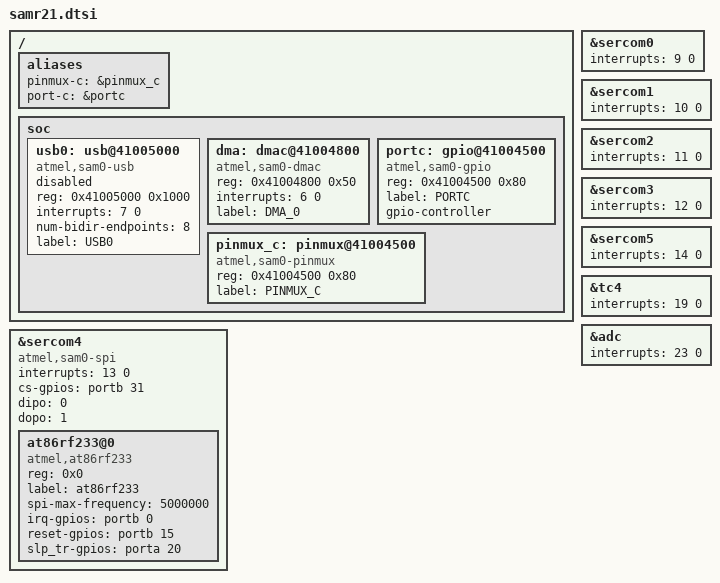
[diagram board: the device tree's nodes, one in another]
/*
 * Copyright (c) 2019 Benjamin Valentin
 *
 * SPDX-License-Identifier: Apache-2.0
 */

#include <atmel/samd.dtsi>

/ {
	aliases {
		pinmux-c = &pinmux_c;
		port-c = &portc;
	};

	soc {
		usb0: usb@41005000 {
			compatible = "atmel,sam0-usb";
			status = "disabled";
			reg = <0x41005000 0x1000>;
			interrupts = <7 0>;
			num-bidir-endpoints = <8>;
			label = "USB0";
		};

		dma: dmac@41004800 {
			compatible = "atmel,sam0-dmac";
			reg = <0x41004800 0x50>;
			interrupts = <6 0>;
			label = "DMA_0";
		};

		portc: gpio@41004500 {
			compatible = "atmel,sam0-gpio";
			reg = <0x41004500 0x80>;
			label = "PORTC";
			gpio-controller;
			#gpio-cells = <2>;
		};

		pinmux_c: pinmux@41004500 {
			compatible = "atmel,sam0-pinmux";
			reg = <0x41004500 0x80>;
			label = "PINMUX_C";
		};
	};
};

&sercom0 {
	interrupts = <9 0>;
};

&sercom1 {
	interrupts = <10 0>;
};

&sercom2 {
	interrupts = <11 0>;
};

&sercom3 {
	interrupts = <12 0>;
};

&sercom4 {
	interrupts = <13 0>;

	status = "ok";

	compatible = "atmel,sam0-spi";
	cs-gpios = <&portb 31 0>;
	dipo = <0>;
	dopo = <1>;

	#address-cells = <1>;
	#size-cells = <0>;

	at86rf233@0 {
		reg = <0x0>;
		compatible = "atmel,at86rf233";
		label = "at86rf233";
		spi-max-frequency = <5000000>;
		irq-gpios = <&portb 0 0>;
		reset-gpios = <&portb 15 0>;
		slp_tr-gpios = <&porta 20 0>;
		status = "ok";
	};
};

&sercom5 {
	interrupts = <14 0>;
};

&tc4 {
	interrupts = <19 0>;
};

&adc {
	interrupts = <23 0>;
};
